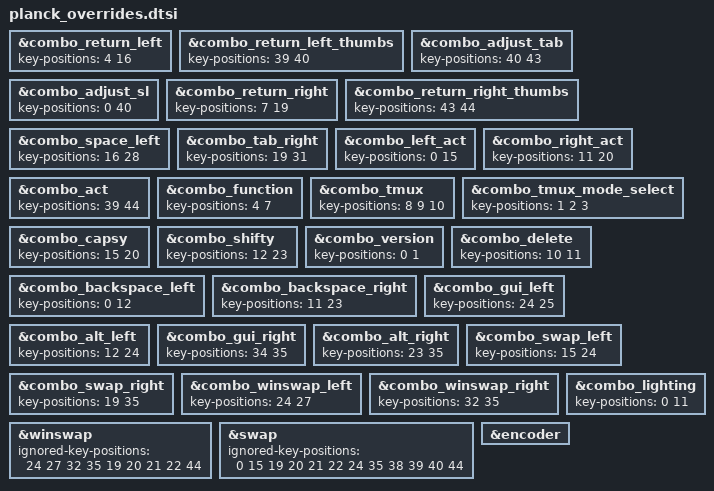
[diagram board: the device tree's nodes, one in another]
/* Key Positions
╭────────────────────────────────────────────────────╮
│  0   1   2   3   4     5   6     7   8   9  10  11 │
│ 12  13  14  15  16    17  18    19  20  21  22  23 │
│ 24  25  26  27  28    29  30    31  32  33  34  35 │
│ 36  37  38  39  40    41  42    43  44  45  46  47 │
╰────────────────────────────────────────────────────╯
*/
// DEFINES {{{
#undef  LEFT_POSITIONS
#define LEFT_POSITIONS  0 1 2 3 4 12 13 14 15 16 24 25 26 27 28 36 37 38 39 40
#undef  RIGHT_POSITIONS
#define RIGHT_POSITIONS 7 8 9 10 11 19 20 21 22 23 31 32 33 34 35 43 44 45 46 47
// }}}
// COMBOS {{{
&combo_return_left {
    key-positions = <4 16>;
};
&combo_return_left_thumbs {
    key-positions = <39 40>;
};
&combo_adjust_tab {
    key-positions = <40 43>;
};
&combo_adjust_sl {
    key-positions = <0 40>;
};
&combo_return_right {
    key-positions = <7 19>;
};
&combo_return_right_thumbs {
    key-positions = <43 44>;
};
&combo_space_left {
    key-positions = <16 28>;
};
&combo_tab_right {
    key-positions = <19 31>;
};
&combo_left_act {
    key-positions = <0  15>;
};
&combo_right_act {
    key-positions = <11 20>;
};
&combo_act {
    key-positions = <39 44>;
};
&combo_function {
    key-positions = <4 7>;
};
&combo_tmux {
    key-positions = <8 9 10>;
};
&combo_tmux_mode_select {
    key-positions = <1 2 3>;
};
&combo_capsy {
    key-positions = <15 20>;
};
&combo_shifty {
    key-positions = <12 23>;
};
&combo_version {
    key-positions = <0 1>;
};
&combo_delete {
    key-positions = <10 11>;
};
&combo_backspace_left {
    key-positions = <0 12>;
};
&combo_backspace_right {
    key-positions = <11 23>;
};
&combo_gui_left {
    key-positions = <24 25>;
};
&combo_alt_left {
    key-positions = <12 24>;
};
&combo_gui_right {
    key-positions = <34 35>;
};
&combo_alt_right {
    key-positions = <23 35>;
};
&combo_swap_left {
    key-positions = <15 24>;
};
&combo_swap_right {
    key-positions = <19 35>;
};
&combo_winswap_left {
    key-positions = <24 27>;
};
&combo_winswap_right {
    key-positions = <32 35>;
};
&combo_lighting {
    key-positions = <0 11>;
};
// }}}
// BEHAVIORS {{{
&winswap {
    ignored-key-positions = <24 27 32 35 19 20 21 22 44>;
};
&swap {
    // must include activating combo keys too (15 24, 19 35) or else tri-state will complete immediately for Mac
    // include hjkl (19 20 21 22) and nav layer activation (44) for navigation
    // include mode keys: h to hide (19), q to quit (0)
    // include lhs arrow key shortcuts: 38 39 40
    ignored-key-positions = <0 15 19 20 21 22 24 35 38 39 40 44>;
};
// }}}
// FEATURES {{{
&encoder {
    status = "okay";
};
// }}}
/* vim: set ft=dts: */
